# STM32WB35CCU6A register map
File version: 1.0
Registers are 32-bit, access not given, reset 0x0 unless marked. A register's access mark holds for its fields unless they carry their own. Offsets are from the block's base; [hi:lo] are bit positions; {n}, {i} and the like mark numbered series.

## CRS
Base 0x40006000
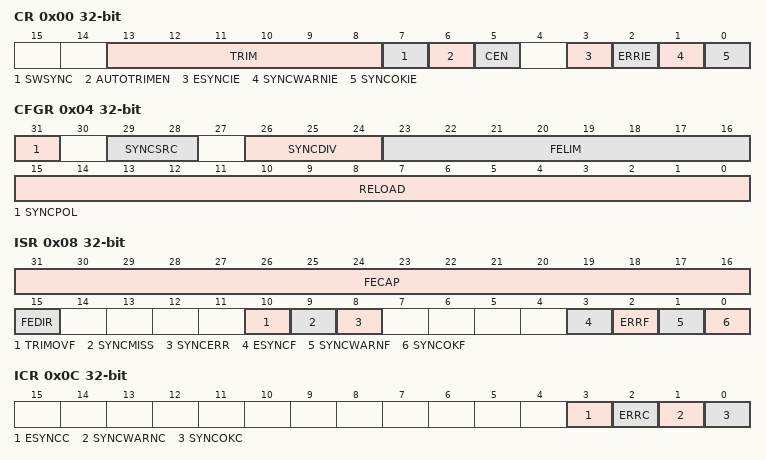
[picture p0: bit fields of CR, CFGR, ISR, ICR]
0x00 CR
  [13:8] TRIM, [7] SWSYNC, [6] AUTOTRIMEN, [5] CEN, [3] ESYNCIE, [2] ERRIE, [1] SYNCWARNIE, [0] SYNCOKIE
0x04 CFGR
  [31] SYNCPOL, [29:28] SYNCSRC, [26:24] SYNCDIV, [23:16] FELIM, [15:0] RELOAD
0x08 ISR
  [31:16] FECAP, [15] FEDIR, [10] TRIMOVF, [9] SYNCMISS, [8] SYNCERR, [3] ESYNCF, [2] ERRF, [1] SYNCWARNF, [0] SYNCOKF
0x0C ICR
  [3] ESYNCC, [2] ERRC, [1] SYNCWARNC, [0] SYNCOKC

## USBFS
Base 0x40006800
Same registers: USBSRAM 0x40006C00
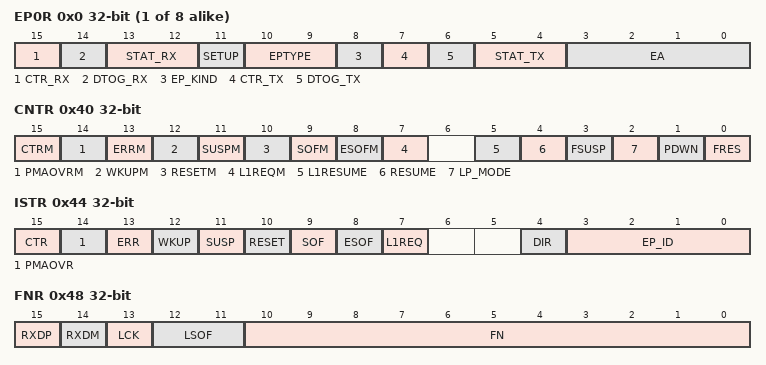
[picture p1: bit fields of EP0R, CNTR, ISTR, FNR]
{0x0+4i} EP{i}R (i=0..7)
  [15] CTR_RX, [14] DTOG_RX, [13:12] STAT_RX, [11] SETUP, [10:9] EPTYPE, [8] EP_KIND, [7] CTR_TX, [6] DTOG_TX, [5:4] STAT_TX, [3:0] EA
0x40 CNTR
  [15] CTRM, [14] PMAOVRM, [13] ERRM, [12] WKUPM, [11] SUSPM, [10] RESETM, [9] SOFM, [8] ESOFM, [7] L1REQM, [5] L1RESUME, [4] RESUME, [3] FSUSP, [2] LP_MODE, [1] PDWN, [0] FRES
0x44 ISTR
  [15] CTR, [14] PMAOVR, [13] ERR, [12] WKUP, [11] SUSP, [10] RESET, [9] SOF, [8] ESOF, [7] L1REQ, [4] DIR, [3:0] EP_ID
0x48 FNR
  [15] RXDP, [14] RXDM, [13] LCK, [12:11] LSOF, [10:0] FN
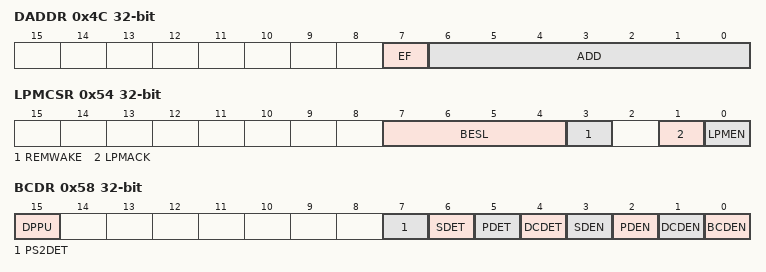
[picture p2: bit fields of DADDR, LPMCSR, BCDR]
0x4C DADDR
  [7] EF, [6:0] ADD
0x50 BTABLE
  [15:3] BTABLE
0x54 LPMCSR
  [7:4] BESL, [3] REMWAKE, [1] LPMACK, [0] LPMEN
0x58 BCDR
  [15] DPPU, [7] PS2DET, [6] SDET, [5] PDET, [4] DCDET, [3] SDEN, [2] PDEN, [1] DCDEN, [0] BCDEN

## LPTIM1
Base 0x40007C00
Same registers: LPTIM2 0x40009400
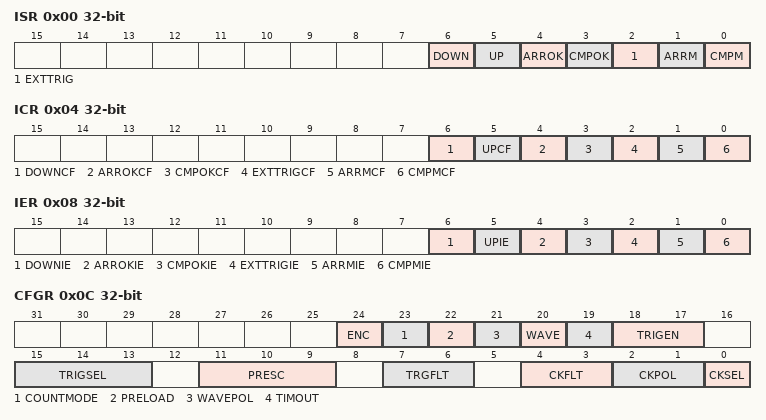
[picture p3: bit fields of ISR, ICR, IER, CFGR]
0x00 ISR
  [6] DOWN, [5] UP, [4] ARROK, [3] CMPOK, [2] EXTTRIG, [1] ARRM, [0] CMPM
0x04 ICR
  [6] DOWNCF, [5] UPCF, [4] ARROKCF, [3] CMPOKCF, [2] EXTTRIGCF, [1] ARRMCF, [0] CMPMCF
0x08 IER
  [6] DOWNIE, [5] UPIE, [4] ARROKIE, [3] CMPOKIE, [2] EXTTRIGIE, [1] ARRMIE, [0] CMPMIE
0x0C CFGR
  [24] ENC, [23] COUNTMODE, [22] PRELOAD, [21] WAVEPOL, [20] WAVE, [19] TIMOUT, [18:17] TRIGEN, [15:13] TRIGSEL, [11:9] PRESC, [7:6] TRGFLT, [4:3] CKFLT, [2:1] CKPOL, [0] CKSEL
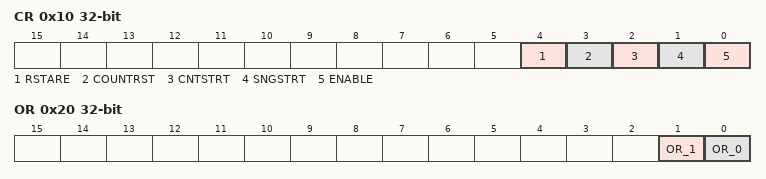
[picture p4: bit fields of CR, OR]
0x10 CR
  [4] RSTARE, [3] COUNTRST, [2] CNTSTRT, [1] SNGSTRT, [0] ENABLE
0x14 CMP
  [15:0] CMP
0x18 ARR
  [15:0] ARR
0x1C CNT
  [15:0] CNT
0x20 OR
  [1] OR_1, [0] OR_0

## LPUART1
Base 0x40008000
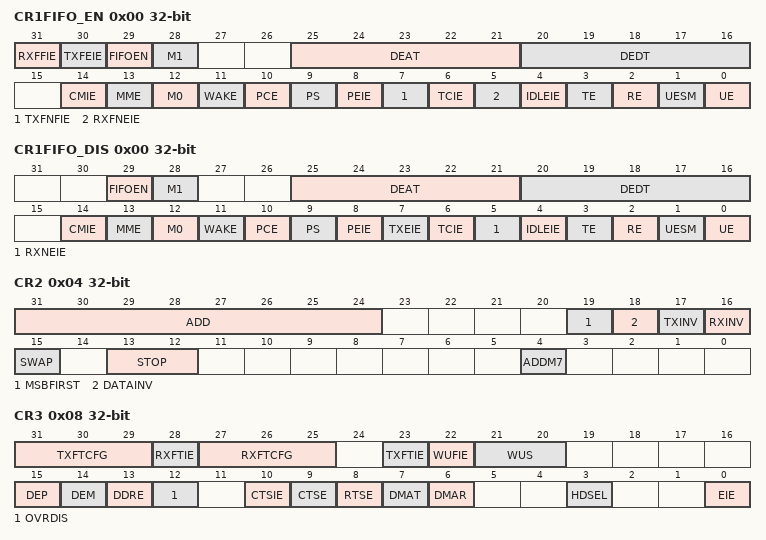
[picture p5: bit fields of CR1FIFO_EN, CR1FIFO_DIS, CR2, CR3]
0x00 CR1FIFO_EN
  [31] RXFFIE, [30] TXFEIE, [29] FIFOEN, [28] M1, [25:21] DEAT, [20:16] DEDT, [14] CMIE, [13] MME, [12] M0, [11] WAKE, [10] PCE, [9] PS, [8] PEIE, [7] TXFNFIE, [6] TCIE, [5] RXFNEIE, [4] IDLEIE, [3] TE, [2] RE, [1] UESM, [0] UE
0x00 CR1FIFO_DIS
  [29] FIFOEN, [28] M1, [25:21] DEAT, [20:16] DEDT, [14] CMIE, [13] MME, [12] M0, [11] WAKE, [10] PCE, [9] PS, [8] PEIE, [7] TXEIE, [6] TCIE, [5] RXNEIE, [4] IDLEIE, [3] TE, [2] RE, [1] UESM, [0] UE
0x04 CR2
  [31:24] ADD, [19] MSBFIRST, [18] DATAINV, [17] TXINV, [16] RXINV, [15] SWAP, [13:12] STOP, [4] ADDM7
0x08 CR3
  [31:29] TXFTCFG, [28] RXFTIE, [27:25] RXFTCFG, [23] TXFTIE, [22] WUFIE, [21:20] WUS, [15] DEP, [14] DEM, [13] DDRE, [12] OVRDIS, [10] CTSIE, [9] CTSE, [8] RTSE, [7] DMAT, [6] DMAR, [3] HDSEL, [0] EIE
0x0C BRR
  [19:0] BRR
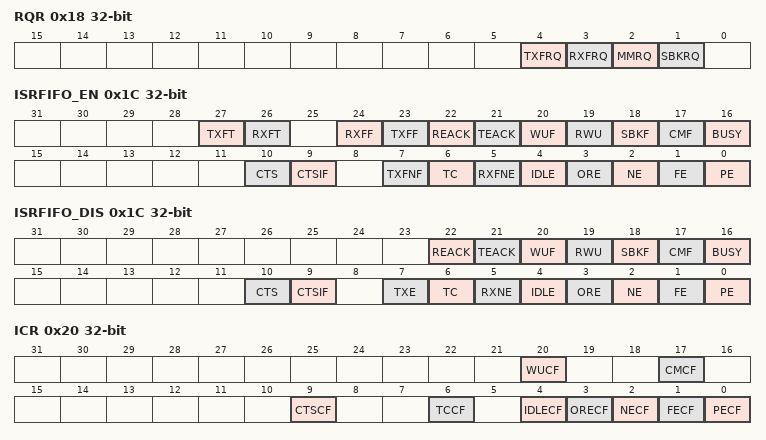
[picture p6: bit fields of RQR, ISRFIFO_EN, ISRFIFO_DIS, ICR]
0x18 RQR
  [4] TXFRQ, [3] RXFRQ, [2] MMRQ, [1] SBKRQ
0x1C ISRFIFO_EN
  [27] TXFT, [26] RXFT, [24] RXFF, [23] TXFF, [22] REACK, [21] TEACK, [20] WUF, [19] RWU, [18] SBKF, [17] CMF, [16] BUSY, [10] CTS, [9] CTSIF, [7] TXFNF, [6] TC, [5] RXFNE, [4] IDLE, [3] ORE, [2] NE, [1] FE, [0] PE
0x1C ISRFIFO_DIS
  [22] REACK, [21] TEACK, [20] WUF, [19] RWU, [18] SBKF, [17] CMF, [16] BUSY, [10] CTS, [9] CTSIF, [7] TXE, [6] TC, [5] RXNE, [4] IDLE, [3] ORE, [2] NE, [1] FE, [0] PE
0x20 ICR
  [20] WUCF, [17] CMCF, [9] CTSCF, [6] TCCF, [4] IDLECF, [3] ORECF, [2] NECF, [1] FECF, [0] PECF
0x24 RDR
  [8:0] RDR
0x28 TDR
  [8:0] TDR
0x2C PRESC
  [3:0] PRESCALER

## SYSCFG
Base 0x40010000
Same registers: SYSCFG 0x40010100, SYSCFG 0x40010100
0x00 MEMRMP
  [2:0] MEM_MODE
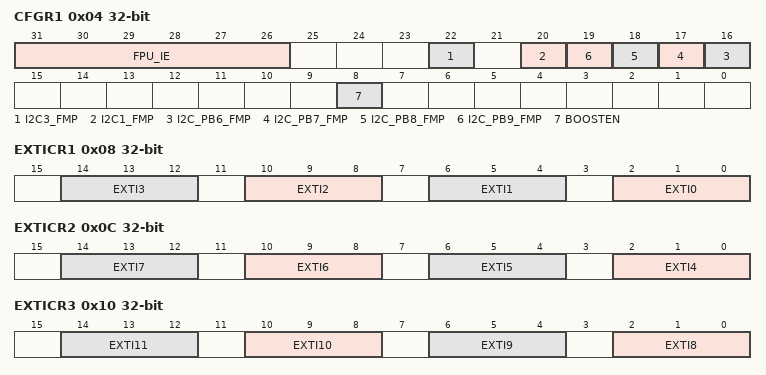
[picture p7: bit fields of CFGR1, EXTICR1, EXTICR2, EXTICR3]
0x04 CFGR1
  [31:26] FPU_IE, [22] I2C3_FMP, [20] I2C1_FMP, [n+10] I2C_PB{n}_FMP (n=6..9), [8] BOOSTEN
0x08 EXTICR1
  [4n+2:4n] EXTI{n} (n=0..3)
0x0C EXTICR2
  [4n-14:4n-16] EXTI{n} (n=4..7)
0x10 EXTICR3
  [4n-30:4n-32] EXTI{n} (n=8..11)
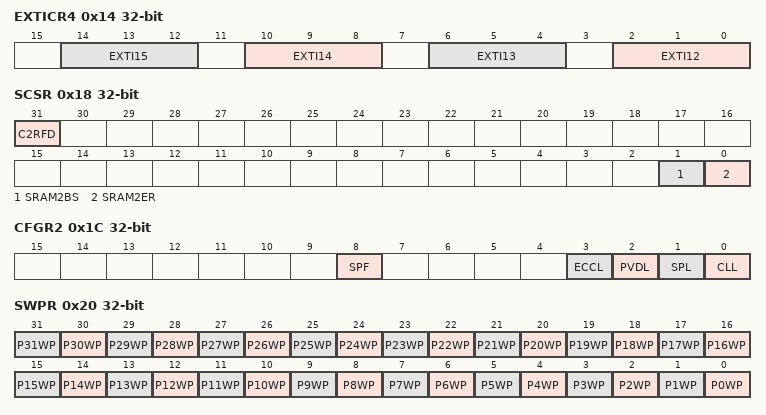
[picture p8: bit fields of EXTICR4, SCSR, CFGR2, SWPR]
0x14 EXTICR4
  [4n-46:4n-48] EXTI{n} (n=12..15)
0x18 SCSR
  [31] C2RFD, [1] SRAM2BS, [0] SRAM2ER
0x1C CFGR2
  [8] SPF, [3] ECCL, [2] PVDL, [1] SPL, [0] CLL
0x20 SWPR
  [n] P{n}WP (n=0..31)
0x24 SKR
  [7:0] KEY
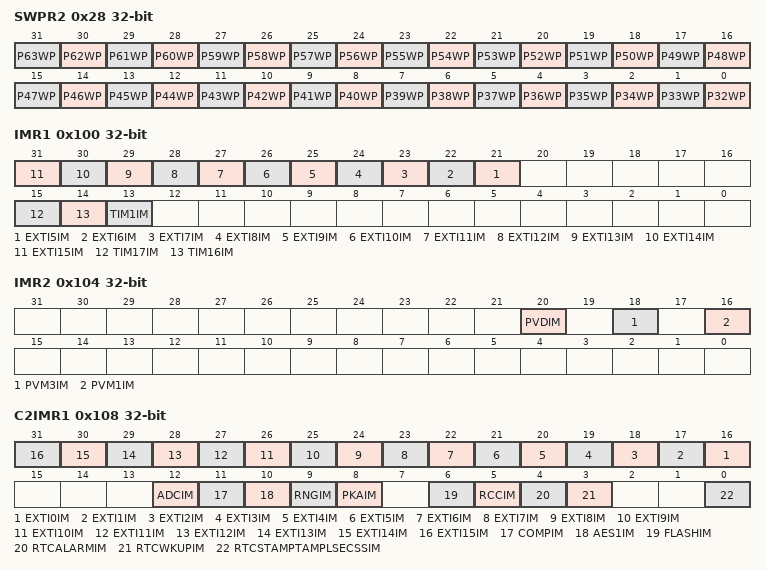
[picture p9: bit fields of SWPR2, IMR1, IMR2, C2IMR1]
0x28 SWPR2
  [n-32] P{n}WP (n=32..63)
0x100 IMR1
  [n+16] EXTI{n}IM (n=5..15), [15] TIM17IM, [14] TIM16IM, [13] TIM1IM
0x104 IMR2
  [20] PVDIM, [18] PVM3IM, [16] PVM1IM
0x108 C2IMR1
  [n+16] EXTI{n}IM (n=0..15), [12] ADCIM, [11] COMPIM, [10] AES1IM, [9] RNGIM, [8] PKAIM, [6] FLASHIM, [5] RCCIM, [4] RTCALARMIM, [3] RTCWKUPIM, [0] RTCSTAMPTAMPLSECSSIM
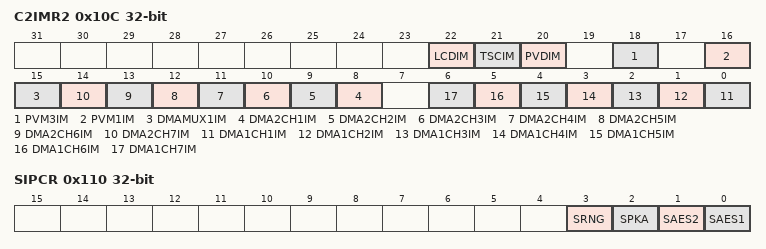
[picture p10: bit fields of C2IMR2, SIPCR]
0x10C C2IMR2
  [22] LCDIM, [21] TSCIM, [20] PVDIM, [18] PVM3IM, [16] PVM1IM, [15] DMAMUX1IM, [n+7] DMA2CH{n}IM (n=1..7), [n-1] DMA1CH{n}IM (n=1..7)
0x110 SIPCR
  [3] SRNG, [2] SPKA, [1] SAES2, [0] SAES1
